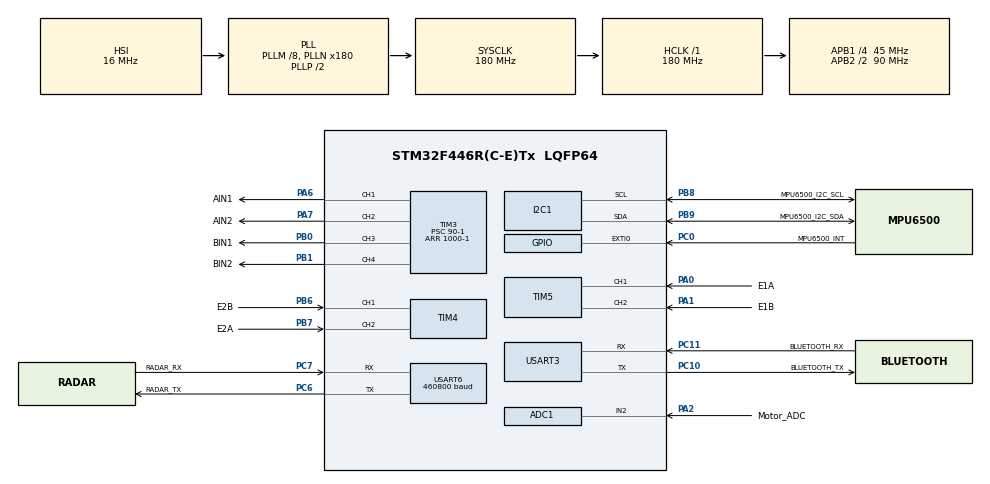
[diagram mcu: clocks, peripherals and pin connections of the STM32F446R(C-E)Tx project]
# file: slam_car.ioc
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ADC1.Channel-0\#ChannelRegularConversion=ADC_CHANNEL_2
ADC1.ContinuousConvMode=ENABLE
ADC1.NbrOfConversion=1
ADC1.NbrOfConversionFlag=1
ADC1.Rank-0\#ChannelRegularConversion=1
ADC1.SamplingTime-0\#ChannelRegularConversion=ADC_SAMPLETIME_28CYCLES
ADC1.master=1
Dma.Request0=USART3_TX
Dma.USART3_TX.0.Direction=DMA_MEMORY_TO_PERIPH
Dma.USART3_TX.0.FIFOMode=DMA_FIFOMODE_DISABLE
Dma.USART3_TX.0.Instance=DMA1_Stream3
Dma.USART3_TX.0.MemDataAlignment=DMA_MDATAALIGN_BYTE
Dma.USART3_TX.0.MemInc=DMA_MINC_ENABLE
Dma.USART3_TX.0.Mode=DMA_NORMAL
Dma.USART3_TX.0.PeriphDataAlignment=DMA_PDATAALIGN_BYTE
Dma.USART3_TX.0.PeriphInc=DMA_PINC_DISABLE
Dma.USART3_TX.0.Priority=DMA_PRIORITY_HIGH
FREERTOS.Tasks01=defaultTask,24,128,StartDefaultTask,Default,NULL,Dynamic,NULL,NULL;MPU_Task,8,128,MPU_Task_Start,Default,NULL,Dynamic,NULL,NULL;FSM_MOTOR_Task,8,128,FSM_MOTOR_Task_Start,Default,NULL,Dynamic,NULL,NULL;BLUETOOTH_Task,8,128,BLUETOOTH_Task_Start,Default,NULL,Dynamic,NULL,NULL;RPLIDAR_Task,8,128,RPLIDAR_Task_Start,Default,NULL,Dynamic,NULL,NULL
I2C1.I2C_Mode=I2C_Fast
Mcu.Family=STM32F4
Mcu.Name=STM32F446R(C-E)Tx
Mcu.Package=LQFP64
NVIC.DMA1_Stream3_IRQn=true\:5\:0\:false\:false\:true\:true\:false\:true\:true
NVIC.EXTI0_IRQn=true\:5\:0\:false\:false\:true\:true\:true\:true\:true
NVIC.I2C1_ER_IRQn=true\:5\:0\:false\:false\:true\:true\:true\:true\:true
NVIC.I2C1_EV_IRQn=true\:5\:0\:false\:false\:true\:true\:true\:true\:true
NVIC.PriorityGroup=NVIC_PRIORITYGROUP_4
NVIC.TIM6_DAC_IRQn=true\:5\:0\:false\:false\:true\:true\:true\:true\:true
NVIC.USART3_IRQn=true\:5\:0\:false\:false\:true\:true\:true\:true\:true
NVIC.USART6_IRQn=true\:5\:0\:false\:false\:true\:true\:true\:true\:true
PA0-WKUP.GPIO_Label=E1A
PA0-WKUP.Signal=S_TIM5_CH1
PA1.GPIO_Label=E1B
PA1.Signal=S_TIM5_CH2
PA2.GPIO_Label=Motor_ADC
PA2.Signal=ADCx_IN2
PA6.GPIO_Label=AIN1
PA6.Signal=S_TIM3_CH1
PA7.GPIO_Label=AIN2
PA7.Signal=S_TIM3_CH2
PB0.GPIO_Label=BIN1
PB0.Signal=S_TIM3_CH3
PB1.GPIO_Label=BIN2
PB1.Signal=S_TIM3_CH4
PB6.GPIO_Label=E2B
PB6.Signal=S_TIM4_CH1
PB7.GPIO_Label=E2A
PB7.Signal=S_TIM4_CH2
PB8.GPIO_Label=MPU6500_I2C_SCL
PB8.Mode=I2C
PB8.Signal=I2C1_SCL
PB9.GPIO_Label=MPU6500_I2C_SDA
PB9.Mode=I2C
PB9.Signal=I2C1_SDA
PC0.GPIO_Label=MPU6500_INT
PC0.GPIO_ModeDefaultEXTI=GPIO_MODE_IT_FALLING
PC0.GPIO_PuPd=GPIO_PULLUP
PC0.Signal=GPXTI0
PC10.GPIO_Label=BLUETOOTH_TX
PC10.Mode=Asynchronous
PC10.Signal=USART3_TX
PC11.GPIO_Label=BLUETOOTH_RX
PC11.Mode=Asynchronous
PC11.Signal=USART3_RX
PC6.GPIO_Label=RADAR_TX
PC6.Mode=Asynchronous
PC6.Signal=USART6_TX
PC7.GPIO_Label=RADAR_RX
PC7.Mode=Asynchronous
PC7.Signal=USART6_RX
PH0-OSC_IN.Mode=HSE-External-Oscillator
PH0-OSC_IN.Signal=RCC_OSC_IN
PH1-OSC_OUT.Mode=HSE-External-Oscillator
PH1-OSC_OUT.Signal=RCC_OSC_OUT
ProjectManager.HeapSize=0x200
ProjectManager.StackSize=0x400
ProjectManager.TargetToolchain=MDK-ARM V5.32
RCC.AHBFreq_Value=180000000
RCC.APB1CLKDivider=RCC_HCLK_DIV4
RCC.APB1Freq_Value=45000000
RCC.APB1TimFreq_Value=90000000
RCC.APB2CLKDivider=RCC_HCLK_DIV2
RCC.APB2Freq_Value=90000000
RCC.APB2TimFreq_Value=180000000
RCC.CortexFreq_Value=180000000
RCC.HCLKFreq_Value=180000000
RCC.PLLM=8
RCC.PLLN=180
RCC.SYSCLKFreq_VALUE=180000000
RCC.SYSCLKSource=RCC_SYSCLKSOURCE_PLLCLK
RCC.USBFreq_Value=180000000
RCC.VCOOutputFreq_Value=360000000
SH.ADCx_IN2.0=ADC1_IN2,IN2
SH.S_TIM3_CH1.0=TIM3_CH1,PWM Generation1 CH1
SH.S_TIM3_CH2.0=TIM3_CH2,PWM Generation2 CH2
SH.S_TIM3_CH3.0=TIM3_CH3,PWM Generation3 CH3
SH.S_TIM3_CH4.0=TIM3_CH4,PWM Generation4 CH4
SH.S_TIM4_CH1.0=TIM4_CH1,Encoder_Interface
SH.S_TIM4_CH2.0=TIM4_CH2,Encoder_Interface
SH.S_TIM5_CH1.0=TIM5_CH1,Encoder_Interface
SH.S_TIM5_CH2.0=TIM5_CH2,Encoder_Interface
TIM3.AutoReloadPreload=TIM_AUTORELOAD_PRELOAD_ENABLE
TIM3.Channel-PWM\ Generation1\ CH1=TIM_CHANNEL_1
TIM3.Channel-PWM\ Generation2\ CH2=TIM_CHANNEL_2
TIM3.Channel-PWM\ Generation3\ CH3=TIM_CHANNEL_3
TIM3.Channel-PWM\ Generation4\ CH4=TIM_CHANNEL_4
TIM3.Period=1000-1
TIM3.Prescaler=90-1
TIM4.AutoReloadPreload=TIM_AUTORELOAD_PRELOAD_ENABLE
TIM4.EncoderMode=TIM_ENCODERMODE_TI12
TIM5.AutoReloadPreload=TIM_AUTORELOAD_PRELOAD_ENABLE
TIM5.EncoderMode=TIM_ENCODERMODE_TI12
TIM6.AutoReloadPreload=TIM_AUTORELOAD_PRELOAD_ENABLE
TIM6.Period=1000-1
TIM6.Prescaler=90-1
USART3.VirtualMode=VM_ASYNC
USART6.BaudRate=460800
USART6.VirtualMode=VM_ASYNC
VP_FREERTOS_VS_CMSIS_V2.Mode=CMSIS_V2
VP_TIM3_VS_ClockSourceINT.Mode=Internal
VP_TIM6_VS_ClockSourceINT.Mode=Enable_Timer
board=custom

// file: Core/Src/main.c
/* USER CODE BEGIN Header */
/**
  ******************************************************************************
  * @file           : main.c
  * @brief          : Main program body
  ******************************************************************************
  * @attention
  *
  * Copyright (c) 2025 STMicroelectronics.
  * All rights reserved.
  *
  * This software is licensed under terms that can be found in the LICENSE file
  * in the root directory of this software component.
  * If no LICENSE file comes with this software, it is provided AS-IS.
  *
  ******************************************************************************
  */
/* USER CODE END Header */
#include "main.h"
#include "cmsis_os.h"
#include "adc.h"
#include "dma.h"
#include "i2c.h"
#include "tim.h"
#include "usart.h"
#include "gpio.h"

/* USER CODE BEGIN Includes */
#include <string.h>
#include "motor.h"
#include "pid.h"
#include "dwt.h"
#include "delay.h"
#include "mpu6500_driver.h"
#include "rplidar.h"
#include "bluetooth.h"
#include "FSM.h"

#include "NVIC_Callback.h"

/* USER CODE END Includes */

void SystemClock_Config(void);
void MX_FREERTOS_Init(void);

int main(void)
{

  /* MCU Configuration--------------------------------------------------------*/

  /* Reset of all peripherals, Initializes the Flash interface and the Systick. */
  HAL_Init();

  /* Configure the system clock */
  SystemClock_Config();

  /* USER CODE BEGIN SysInit */
  DWT_Init();

  /* USER CODE END SysInit */

  /* Initialize all configured peripherals */
  MX_GPIO_Init();
  MX_DMA_Init();
  MX_ADC1_Init();
  MX_I2C1_Init();
  MX_TIM3_Init();
  MX_TIM4_Init();
  MX_TIM5_Init();
  MX_USART3_UART_Init();
  MX_USART6_UART_Init();
  MX_TIM6_Init();

  /* Init scheduler */
  osKernelInitialize();

  /* Call init function for freertos objects (in cmsis_os2.c) */
  MX_FREERTOS_Init();

  /* Start scheduler */
  osKernelStart();

  /* We should never get here as control is now taken by the scheduler */

  /* Infinite loop */
  while (1)
  {

  }
}

void SystemClock_Config(void)
{
  RCC_OscInitTypeDef RCC_OscInitStruct = {0};
  RCC_ClkInitTypeDef RCC_ClkInitStruct = {0};

  /** Configure the main internal regulator output voltage
  */
  __HAL_RCC_PWR_CLK_ENABLE();
  __HAL_PWR_VOLTAGESCALING_CONFIG(PWR_REGULATOR_VOLTAGE_SCALE1);

  /** Initializes the RCC Oscillators according to the specified parameters
  * in the RCC_OscInitTypeDef structure.
  */
  RCC_OscInitStruct.OscillatorType = RCC_OSCILLATORTYPE_HSI;
  RCC_OscInitStruct.HSIState = RCC_HSI_ON;
  RCC_OscInitStruct.HSICalibrationValue = RCC_HSICALIBRATION_DEFAULT;
  RCC_OscInitStruct.PLL.PLLState = RCC_PLL_ON;
  RCC_OscInitStruct.PLL.PLLSource = RCC_PLLSOURCE_HSI;
  RCC_OscInitStruct.PLL.PLLM = 8;
  RCC_OscInitStruct.PLL.PLLN = 180;
  RCC_OscInitStruct.PLL.PLLP = RCC_PLLP_DIV2;
  RCC_OscInitStruct.PLL.PLLQ = 2;
  RCC_OscInitStruct.PLL.PLLR = 2;
  if (HAL_RCC_OscConfig(&RCC_OscInitStruct) != HAL_OK)
  {
    Error_Handler();
  }

  /** Activate the Over-Drive mode
  */
  if (HAL_PWREx_EnableOverDrive() != HAL_OK)
  {
    Error_Handler();
  }

  /** Initializes the CPU, AHB and APB buses clocks
  */
  RCC_ClkInitStruct.ClockType = RCC_CLOCKTYPE_HCLK|RCC_CLOCKTYPE_SYSCLK
                              |RCC_CLOCKTYPE_PCLK1|RCC_CLOCKTYPE_PCLK2;
  RCC_ClkInitStruct.SYSCLKSource = RCC_SYSCLKSOURCE_PLLCLK;
  RCC_ClkInitStruct.AHBCLKDivider = RCC_SYSCLK_DIV1;
  RCC_ClkInitStruct.APB1CLKDivider = RCC_HCLK_DIV4;
  RCC_ClkInitStruct.APB2CLKDivider = RCC_HCLK_DIV2;

  if (HAL_RCC_ClockConfig(&RCC_ClkInitStruct, FLASH_LATENCY_5) != HAL_OK)
  {
    Error_Handler();
  }
}

void Error_Handler(void)
{
  __disable_irq();
  while (1)
  {
  }
}
